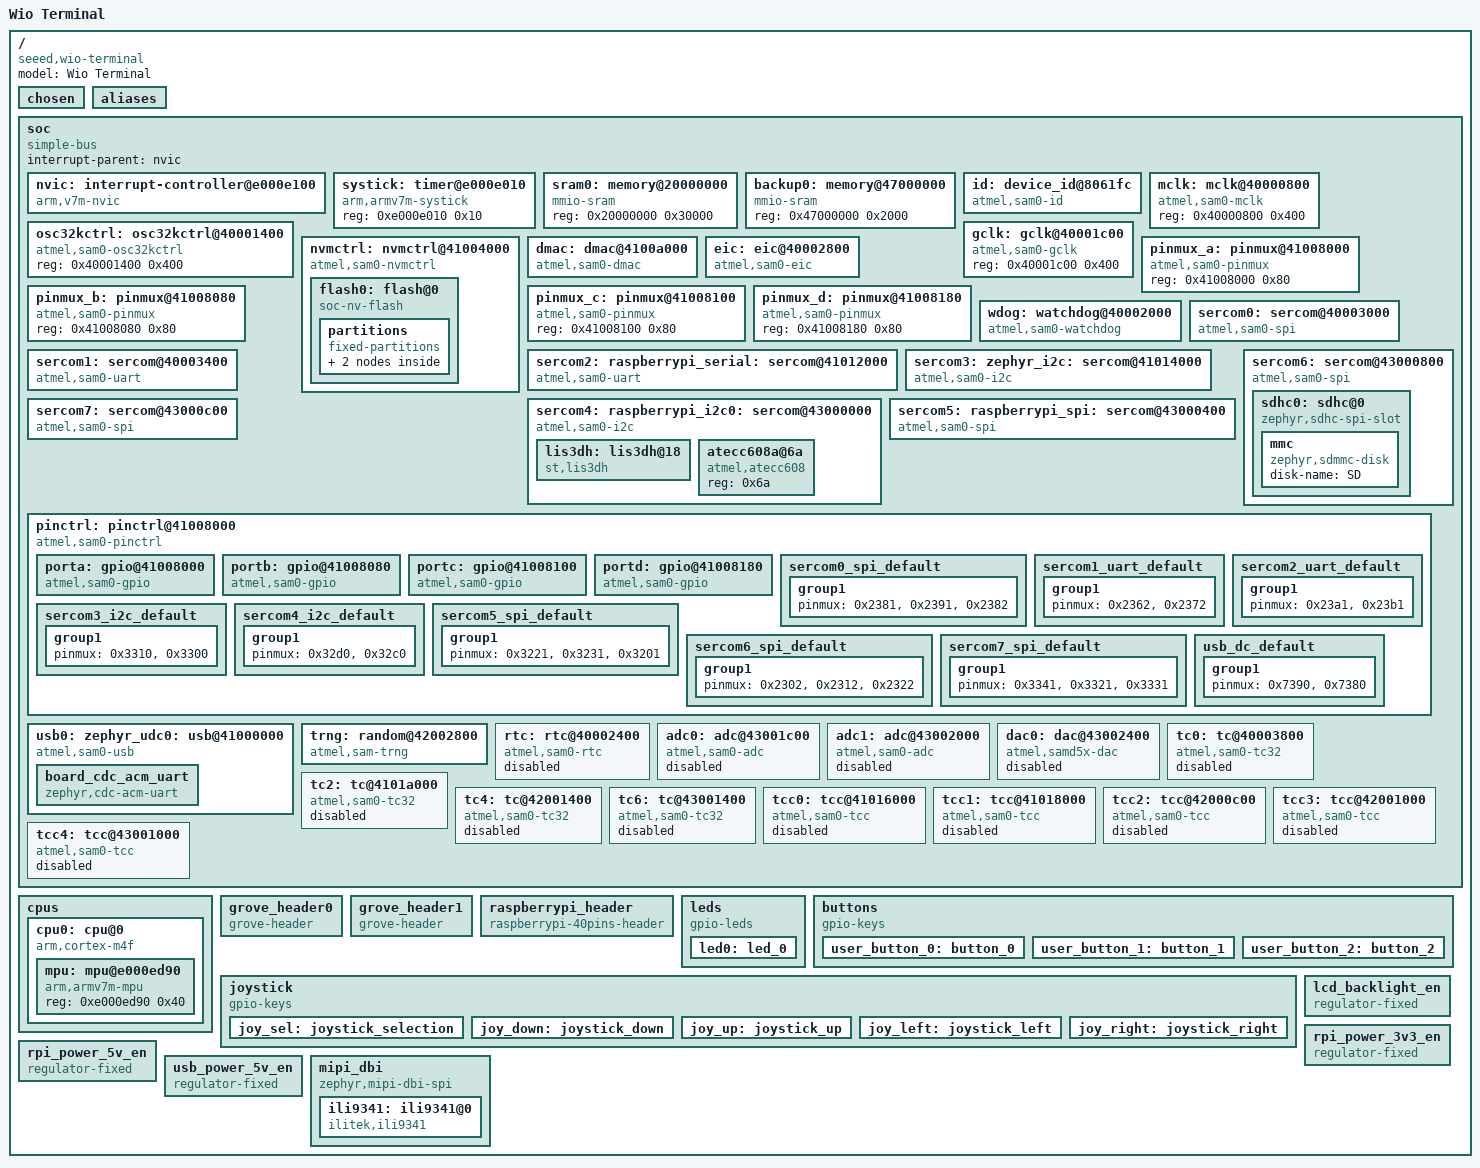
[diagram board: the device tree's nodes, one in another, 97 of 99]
/dts-v1/;

/* node '/' defined in zephyr/dts/common/skeleton.dtsi:9 */
/ {
	#address-cells = < 0x1 >;          /* in zephyr/dts/common/skeleton.dtsi:10 */
	#size-cells = < 0x1 >;             /* in zephyr/dts/common/skeleton.dtsi:11 */
	model = "Wio Terminal";            /* in zephyr/boards/seeed/wio_terminal/wio_terminal.dts:15 */
	compatible = "seeed,wio-terminal"; /* in zephyr/boards/seeed/wio_terminal/wio_terminal.dts:16 */

	/* node '/chosen' defined in zephyr/dts/common/skeleton.dtsi:13 */
	chosen {
		zephyr,entropy = &trng;                   /* in zephyr/dts/arm/atmel/samd5x.dtsi:51 */
		zephyr,flash-controller = &nvmctrl;       /* in zephyr/dts/arm/atmel/samd5x.dtsi:52 */
		zephyr,sram = &sram0;                     /* in zephyr/boards/seeed/wio_terminal/wio_terminal.dts:19 */
		zephyr,flash = &flash0;                   /* in zephyr/boards/seeed/wio_terminal/wio_terminal.dts:20 */
		zephyr,code-partition = &code_partition;  /* in zephyr/boards/seeed/wio_terminal/wio_terminal.dts:21 */
		zephyr,display = &ili9341;                /* in zephyr/boards/seeed/wio_terminal/wio_terminal.dts:22 */
		zephyr,console = &board_cdc_acm_uart;     /* in zephyr/boards/common/usb/cdc_acm_serial.dtsi:9 */
		zephyr,shell-uart = &board_cdc_acm_uart;  /* in zephyr/boards/common/usb/cdc_acm_serial.dtsi:10 */
		zephyr,uart-mcumgr = &board_cdc_acm_uart; /* in zephyr/boards/common/usb/cdc_acm_serial.dtsi:11 */
		zephyr,bt-mon-uart = &board_cdc_acm_uart; /* in zephyr/boards/common/usb/cdc_acm_serial.dtsi:12 */
		zephyr,bt-c2h-uart = &board_cdc_acm_uart; /* in zephyr/boards/common/usb/cdc_acm_serial.dtsi:13 */
	};

	/* node '/aliases' defined in zephyr/dts/common/skeleton.dtsi:15 */
	aliases {
		adc-0 = &adc0;        /* in zephyr/dts/arm/atmel/samd5x.dtsi:16 */
		adc-1 = &adc1;        /* in zephyr/dts/arm/atmel/samd5x.dtsi:17 */
		port-a = &porta;      /* in zephyr/dts/arm/atmel/samd5x.dtsi:19 */
		port-b = &portb;      /* in zephyr/dts/arm/atmel/samd5x.dtsi:20 */
		port-c = &portc;      /* in zephyr/dts/arm/atmel/samd5x.dtsi:21 */
		port-d = &portd;      /* in zephyr/dts/arm/atmel/samd5x.dtsi:22 */
		rtc = &rtc;           /* in zephyr/dts/arm/atmel/samd5x.dtsi:24 */
		sercom-0 = &sercom0;  /* in zephyr/dts/arm/atmel/samd5x.dtsi:26 */
		sercom-1 = &sercom1;  /* in zephyr/dts/arm/atmel/samd5x.dtsi:27 */
		sercom-2 = &sercom2;  /* in zephyr/dts/arm/atmel/samd5x.dtsi:28 */
		sercom-3 = &sercom3;  /* in zephyr/dts/arm/atmel/samd5x.dtsi:29 */
		sercom-4 = &sercom4;  /* in zephyr/dts/arm/atmel/samd5x.dtsi:30 */
		sercom-5 = &sercom5;  /* in zephyr/dts/arm/atmel/samd5x.dtsi:31 */
		sercom-6 = &sercom6;  /* in zephyr/dts/arm/atmel/samd5x.dtsi:32 */
		sercom-7 = &sercom7;  /* in zephyr/dts/arm/atmel/samd5x.dtsi:33 */
		tc-0 = &tc0;          /* in zephyr/dts/arm/atmel/samd5x.dtsi:35 */
		tc-2 = &tc2;          /* in zephyr/dts/arm/atmel/samd5x.dtsi:36 */
		tc-4 = &tc4;          /* in zephyr/dts/arm/atmel/samd5x.dtsi:37 */
		tc-6 = &tc6;          /* in zephyr/dts/arm/atmel/samd5x.dtsi:38 */
		tcc-0 = &tcc0;        /* in zephyr/dts/arm/atmel/samd5x.dtsi:40 */
		tcc-1 = &tcc1;        /* in zephyr/dts/arm/atmel/samd5x.dtsi:41 */
		tcc-2 = &tcc2;        /* in zephyr/dts/arm/atmel/samd5x.dtsi:42 */
		tcc-3 = &tcc3;        /* in zephyr/dts/arm/atmel/samd5x.dtsi:43 */
		tcc-4 = &tcc4;        /* in zephyr/dts/arm/atmel/samd5x.dtsi:44 */
		watchdog0 = &wdog;    /* in zephyr/dts/arm/atmel/samd5x.dtsi:46 */
		led0 = &led0;         /* in zephyr/boards/seeed/wio_terminal/wio_terminal.dts:27 */
		sw0 = &user_button_0; /* in zephyr/boards/seeed/wio_terminal/wio_terminal.dts:28 */
		sw1 = &user_button_1; /* in zephyr/boards/seeed/wio_terminal/wio_terminal.dts:29 */
		sw2 = &user_button_2; /* in zephyr/boards/seeed/wio_terminal/wio_terminal.dts:30 */
		i2c0 = &sercom4;      /* in zephyr/boards/seeed/wio_terminal/wio_terminal.dts:31 */
		i2c1 = &sercom3;      /* in zephyr/boards/seeed/wio_terminal/wio_terminal.dts:32 */
		spi0 = &sercom5;      /* in zephyr/boards/seeed/wio_terminal/wio_terminal.dts:33 */
		uart0 = &sercom2;     /* in zephyr/boards/seeed/wio_terminal/wio_terminal.dts:34 */
		accel0 = &lis3dh;     /* in zephyr/boards/seeed/wio_terminal/wio_terminal.dts:35 */
		sdhc0 = &sdhc0;       /* in zephyr/boards/seeed/wio_terminal/wio_terminal.dts:36 */
	};

	/* node '/soc' defined in zephyr/dts/arm/armv7-m.dtsi:6 */
	soc {
		#address-cells = < 0x1 >;     /* in zephyr/dts/arm/armv7-m.dtsi:7 */
		#size-cells = < 0x1 >;        /* in zephyr/dts/arm/armv7-m.dtsi:8 */
		compatible = "simple-bus";    /* in zephyr/dts/arm/armv7-m.dtsi:9 */
		interrupt-parent = < &nvic >; /* in zephyr/dts/arm/armv7-m.dtsi:10 */
		ranges;                       /* in zephyr/dts/arm/armv7-m.dtsi:11 */

		/* node '/soc/interrupt-controller@e000e100' defined in zephyr/dts/arm/armv7-m.dtsi:13 */
		nvic: interrupt-controller@e000e100 {
			#address-cells = < 0x1 >;            /* in zephyr/dts/arm/armv7-m.dtsi:14 */
			compatible = "arm,v7m-nvic";         /* in zephyr/dts/arm/armv7-m.dtsi:15 */
			reg = < 0xe000e100 0xc00 >;          /* in zephyr/dts/arm/armv7-m.dtsi:16 */
			interrupt-controller;                /* in zephyr/dts/arm/armv7-m.dtsi:17 */
			#interrupt-cells = < 0x2 >;          /* in zephyr/dts/arm/armv7-m.dtsi:18 */
			arm,num-irq-priority-bits = < 0x3 >; /* in zephyr/dts/arm/atmel/samd5x.dtsi:522 */
			phandle = < 0x1 >;                   /* in zephyr/dts/arm/armv7-m.dtsi:10 */
		};

		/* node '/soc/timer@e000e010' defined in zephyr/dts/arm/armv7-m.dtsi:21 */
		systick: timer@e000e010 {
			compatible = "arm,armv7m-systick"; /* in zephyr/dts/arm/armv7-m.dtsi:22 */
			reg = < 0xe000e010 0x10 >;         /* in zephyr/dts/arm/armv7-m.dtsi:23 */
		};

		/* node '/soc/memory@20000000' defined in zephyr/dts/arm/atmel/samd5x.dtsi:76 */
		sram0: memory@20000000 {
			compatible = "mmio-sram";     /* in zephyr/dts/arm/atmel/samd5x.dtsi:77 */
			reg = < 0x20000000 0x30000 >; /* in zephyr/dts/arm/atmel/samd5xx19.dtsi:19 */
		};

		/* node '/soc/memory@47000000' defined in zephyr/dts/arm/atmel/samd5x.dtsi:81 */
		backup0: memory@47000000 {
			compatible = "mmio-sram";    /* in zephyr/dts/arm/atmel/samd5x.dtsi:82 */
			reg = < 0x47000000 0x2000 >; /* in zephyr/dts/arm/atmel/samd5x.dtsi:83 */
		};

		/* node '/soc/device_id@8061fc' defined in zephyr/dts/arm/atmel/samd5x.dtsi:86 */
		id: device_id@8061fc {
			compatible = "atmel,sam0-id"; /* in zephyr/dts/arm/atmel/samd5x.dtsi:87 */
			reg = < 0x8061fc 0x4 >,
			      < 0x806010 0x4 >,
			      < 0x806014 0x4 >,
			      < 0x806018 0x4 >;       /* in zephyr/dts/arm/atmel/samd5x.dtsi:88 */
		};

		/* node '/soc/mclk@40000800' defined in zephyr/dts/arm/atmel/samd5x.dtsi:94 */
		mclk: mclk@40000800 {
			compatible = "atmel,sam0-mclk"; /* in zephyr/dts/arm/atmel/samd5x.dtsi:95 */
			reg = < 0x40000800 0x400 >;     /* in zephyr/dts/arm/atmel/samd5x.dtsi:96 */
			#clock-cells = < 0x2 >;         /* in zephyr/dts/arm/atmel/samd5x.dtsi:98 */
			phandle = < 0x3 >;              /* in zephyr/dts/arm/atmel/samd5x.dtsi:181 */
		};

		/* node '/soc/osc32kctrl@40001400' defined in zephyr/dts/arm/atmel/samd5x.dtsi:101 */
		osc32kctrl: osc32kctrl@40001400 {
			compatible = "atmel,sam0-osc32kctrl";  /* in zephyr/dts/arm/atmel/samd5x.dtsi:102 */
			reg = < 0x40001400 0x400 >;            /* in zephyr/dts/arm/atmel/samd5x.dtsi:103 */
			#clock-cells = < 0x0 >;                /* in zephyr/dts/arm/atmel/samd5x.dtsi:104 */
			#atmel,assigned-clock-cells = < 0x1 >; /* in zephyr/dts/arm/atmel/samd5x.dtsi:105 */
			phandle = < 0xf >;                     /* in zephyr/dts/arm/atmel/samd5x.dtsi:332 */
		};

		/* node '/soc/gclk@40001c00' defined in zephyr/dts/arm/atmel/samd5x.dtsi:108 */
		gclk: gclk@40001c00 {
			compatible = "atmel,sam0-gclk";        /* in zephyr/dts/arm/atmel/samd5x.dtsi:109 */
			reg = < 0x40001c00 0x400 >;            /* in zephyr/dts/arm/atmel/samd5x.dtsi:110 */
			#clock-cells = < 0x1 >;                /* in zephyr/dts/arm/atmel/samd5x.dtsi:112 */
			#atmel,assigned-clock-cells = < 0x1 >; /* in zephyr/dts/arm/atmel/samd5x.dtsi:113 */
			phandle = < 0x2 >;                     /* in zephyr/dts/arm/atmel/samd5x.dtsi:181 */
		};

		/* node '/soc/nvmctrl@41004000' defined in zephyr/dts/arm/atmel/samd5x.dtsi:116 */
		nvmctrl: nvmctrl@41004000 {
			compatible = "atmel,sam0-nvmctrl"; /* in zephyr/dts/arm/atmel/samd5x.dtsi:117 */
			reg = < 0x41004000 0x22 >;         /* in zephyr/dts/arm/atmel/samd5x.dtsi:118 */
			interrupts = < 0x1d 0x0 >,
			             < 0x1e 0x0 >;         /* in zephyr/dts/arm/atmel/samd5x.dtsi:119 */
			#address-cells = < 0x1 >;          /* in zephyr/dts/arm/atmel/samd5x.dtsi:121 */
			#size-cells = < 0x1 >;             /* in zephyr/dts/arm/atmel/samd5x.dtsi:122 */
			lock-regions = < 0x20 >;           /* in zephyr/dts/arm/atmel/samd5x.dtsi:124 */

			/* node '/soc/nvmctrl@41004000/flash@0' defined in zephyr/dts/arm/atmel/samd5x.dtsi:126 */
			flash0: flash@0 {
				compatible = "soc-nv-flash"; /* in zephyr/dts/arm/atmel/samd5x.dtsi:127 */
				write-block-size = < 0x8 >;  /* in zephyr/dts/arm/atmel/samd5x.dtsi:129 */
				reg = < 0x0 0x80000 >;       /* in zephyr/dts/arm/atmel/samd5xx19.dtsi:14 */

				/* node '/soc/nvmctrl@41004000/flash@0/partitions' defined in zephyr/boards/seeed/wio_terminal/wio_terminal.dts:168 */
				partitions {
					compatible = "fixed-partitions"; /* in zephyr/boards/seeed/wio_terminal/wio_terminal.dts:169 */
					#address-cells = < 0x1 >;        /* in zephyr/boards/seeed/wio_terminal/wio_terminal.dts:170 */
					#size-cells = < 0x1 >;           /* in zephyr/boards/seeed/wio_terminal/wio_terminal.dts:171 */

					/* node '/soc/nvmctrl@41004000/flash@0/partitions/partition@0' defined in zephyr/boards/seeed/wio_terminal/wio_terminal.dts:173 */
					boot_partition: partition@0 {
						label = "uf2";        /* in zephyr/boards/seeed/wio_terminal/wio_terminal.dts:174 */
						reg = < 0x0 0x4000 >; /* in zephyr/boards/seeed/wio_terminal/wio_terminal.dts:175 */
						read-only;            /* in zephyr/boards/seeed/wio_terminal/wio_terminal.dts:176 */
					};

					/* node '/soc/nvmctrl@41004000/flash@0/partitions/partition@4000' defined in zephyr/boards/seeed/wio_terminal/wio_terminal.dts:179 */
					code_partition: partition@4000 {
						label = "code";           /* in zephyr/boards/seeed/wio_terminal/wio_terminal.dts:180 */
						reg = < 0x4000 0x7c000 >; /* in zephyr/boards/seeed/wio_terminal/wio_terminal.dts:181 */
						read-only;                /* in zephyr/boards/seeed/wio_terminal/wio_terminal.dts:182 */
					};
				};
			};
		};

		/* node '/soc/dmac@4100a000' defined in zephyr/dts/arm/atmel/samd5x.dtsi:133 */
		dmac: dmac@4100a000 {
			compatible = "atmel,sam0-dmac"; /* in zephyr/dts/arm/atmel/samd5x.dtsi:134 */
			reg = < 0x4100a000 0x50 >;      /* in zephyr/dts/arm/atmel/samd5x.dtsi:135 */
			interrupts = < 0x1f 0x0 >,
			             < 0x20 0x0 >,
			             < 0x21 0x0 >,
			             < 0x22 0x0 >,
			             < 0x23 0x0 >;      /* in zephyr/dts/arm/atmel/samd5x.dtsi:136 */
			#dma-cells = < 0x2 >;           /* in zephyr/dts/arm/atmel/samd5x.dtsi:139 */
			status = "okay";                /* in zephyr/boards/seeed/wio_terminal/wio_terminal.dts:164 */
		};

		/* node '/soc/eic@40002800' defined in zephyr/dts/arm/atmel/samd5x.dtsi:142 */
		eic: eic@40002800 {
			compatible = "atmel,sam0-eic"; /* in zephyr/dts/arm/atmel/samd5x.dtsi:143 */
			reg = < 0x40002800 0x38 >;     /* in zephyr/dts/arm/atmel/samd5x.dtsi:144 */
			interrupts = < 0xc 0x0 >,
			             < 0xd 0x0 >,
			             < 0xe 0x0 >,
			             < 0xf 0x0 >,
			             < 0x10 0x0 >,
			             < 0x11 0x0 >,
			             < 0x12 0x0 >,
			             < 0x13 0x0 >,
			             < 0x14 0x0 >,
			             < 0x15 0x0 >,
			             < 0x16 0x0 >,
			             < 0x17 0x0 >,
			             < 0x18 0x0 >,
			             < 0x19 0x0 >,
			             < 0x1a 0x0 >,
			             < 0x1b 0x0 >;     /* in zephyr/dts/arm/atmel/samd5x.dtsi:145 */
		};

		/* node '/soc/pinmux@41008000' defined in zephyr/dts/arm/atmel/samd5x.dtsi:151 */
		pinmux_a: pinmux@41008000 {
			compatible = "atmel,sam0-pinmux"; /* in zephyr/dts/arm/atmel/samd5x.dtsi:152 */
			reg = < 0x41008000 0x80 >;        /* in zephyr/dts/arm/atmel/samd5x.dtsi:153 */
		};

		/* node '/soc/pinmux@41008080' defined in zephyr/dts/arm/atmel/samd5x.dtsi:156 */
		pinmux_b: pinmux@41008080 {
			compatible = "atmel,sam0-pinmux"; /* in zephyr/dts/arm/atmel/samd5x.dtsi:157 */
			reg = < 0x41008080 0x80 >;        /* in zephyr/dts/arm/atmel/samd5x.dtsi:158 */
		};

		/* node '/soc/pinmux@41008100' defined in zephyr/dts/arm/atmel/samd5x.dtsi:161 */
		pinmux_c: pinmux@41008100 {
			compatible = "atmel,sam0-pinmux"; /* in zephyr/dts/arm/atmel/samd5x.dtsi:162 */
			reg = < 0x41008100 0x80 >;        /* in zephyr/dts/arm/atmel/samd5x.dtsi:163 */
		};

		/* node '/soc/pinmux@41008180' defined in zephyr/dts/arm/atmel/samd5x.dtsi:166 */
		pinmux_d: pinmux@41008180 {
			compatible = "atmel,sam0-pinmux"; /* in zephyr/dts/arm/atmel/samd5x.dtsi:167 */
			reg = < 0x41008180 0x80 >;        /* in zephyr/dts/arm/atmel/samd5x.dtsi:168 */
		};

		/* node '/soc/watchdog@40002000' defined in zephyr/dts/arm/atmel/samd5x.dtsi:171 */
		wdog: watchdog@40002000 {
			compatible = "atmel,sam0-watchdog"; /* in zephyr/dts/arm/atmel/samd5x.dtsi:172 */
			reg = < 0x40002000 0xd >;           /* in zephyr/dts/arm/atmel/samd5x.dtsi:173 */
			interrupts = < 0xa 0x0 >;           /* in zephyr/dts/arm/atmel/samd5x.dtsi:174 */
		};

		/* node '/soc/sercom@40003000' defined in zephyr/dts/arm/atmel/samd5x.dtsi:177 */
		sercom0: sercom@40003000 {
			reg = < 0x40003000 0x40 >;             /* in zephyr/dts/arm/atmel/samd5x.dtsi:179 */
			interrupts = < 0x2e 0x0 >,
			             < 0x2f 0x0 >,
			             < 0x30 0x0 >,
			             < 0x31 0x0 >;             /* in zephyr/dts/arm/atmel/samd5x.dtsi:180 */
			clocks = < &gclk 0x7 >,
			         < &mclk 0x14 0xc >;           /* in zephyr/dts/arm/atmel/samd5x.dtsi:181 */
			clock-names = "GCLK",
			              "MCLK";                  /* in zephyr/dts/arm/atmel/samd5x.dtsi:182 */
			atmel,assigned-clocks = < &gclk 0x0 >; /* in zephyr/dts/arm/atmel/samd5x.dtsi:183 */
			atmel,assigned-clock-names = "GCLK";   /* in zephyr/dts/arm/atmel/samd5x.dtsi:184 */
			status = "okay";                       /* in zephyr/boards/seeed/wio_terminal/wio_terminal.dts:189 */
			compatible = "atmel,sam0-spi";         /* in zephyr/boards/seeed/wio_terminal/wio_terminal.dts:190 */
			#address-cells = < 0x1 >;              /* in zephyr/boards/seeed/wio_terminal/wio_terminal.dts:191 */
			#size-cells = < 0x0 >;                 /* in zephyr/boards/seeed/wio_terminal/wio_terminal.dts:192 */
			dipo = < 0x2 >;                        /* in zephyr/boards/seeed/wio_terminal/wio_terminal.dts:193 */
			dopo = < 0x0 >;                        /* in zephyr/boards/seeed/wio_terminal/wio_terminal.dts:194 */
			pinctrl-0 = < &sercom0_spi_default >;  /* in zephyr/boards/seeed/wio_terminal/wio_terminal.dts:195 */
			pinctrl-names = "default";             /* in zephyr/boards/seeed/wio_terminal/wio_terminal.dts:196 */
			cs-gpios = < &portc 0x19 0x1 >;        /* in zephyr/boards/seeed/wio_terminal/wio_terminal.dts:197 */
		};

		/* node '/soc/sercom@40003400' defined in zephyr/dts/arm/atmel/samd5x.dtsi:188 */
		sercom1: sercom@40003400 {
			reg = < 0x40003400 0x40 >;             /* in zephyr/dts/arm/atmel/samd5x.dtsi:190 */
			interrupts = < 0x32 0x0 >,
			             < 0x33 0x0 >,
			             < 0x34 0x0 >,
			             < 0x35 0x0 >;             /* in zephyr/dts/arm/atmel/samd5x.dtsi:191 */
			clocks = < &gclk 0x8 >,
			         < &mclk 0x14 0xd >;           /* in zephyr/dts/arm/atmel/samd5x.dtsi:192 */
			clock-names = "GCLK",
			              "MCLK";                  /* in zephyr/dts/arm/atmel/samd5x.dtsi:193 */
			atmel,assigned-clocks = < &gclk 0x0 >; /* in zephyr/dts/arm/atmel/samd5x.dtsi:194 */
			atmel,assigned-clock-names = "GCLK";   /* in zephyr/dts/arm/atmel/samd5x.dtsi:195 */
			status = "okay";                       /* in zephyr/boards/seeed/wio_terminal/wio_terminal.dts:202 */
			compatible = "atmel,sam0-uart";        /* in zephyr/boards/seeed/wio_terminal/wio_terminal.dts:203 */
			current-speed = < 0x1c200 >;           /* in zephyr/boards/seeed/wio_terminal/wio_terminal.dts:204 */
			rxpo = < 0x1 >;                        /* in zephyr/boards/seeed/wio_terminal/wio_terminal.dts:205 */
			txpo = < 0x0 >;                        /* in zephyr/boards/seeed/wio_terminal/wio_terminal.dts:206 */
			pinctrl-0 = < &sercom1_uart_default >; /* in zephyr/boards/seeed/wio_terminal/wio_terminal.dts:207 */
			pinctrl-names = "default";             /* in zephyr/boards/seeed/wio_terminal/wio_terminal.dts:208 */
		};

		/* node '/soc/sercom@41012000' defined in zephyr/dts/arm/atmel/samd5x.dtsi:199 */
		sercom2: raspberrypi_serial: sercom@41012000 {
			reg = < 0x41012000 0x40 >;             /* in zephyr/dts/arm/atmel/samd5x.dtsi:201 */
			interrupts = < 0x36 0x0 >,
			             < 0x37 0x0 >,
			             < 0x38 0x0 >,
			             < 0x39 0x0 >;             /* in zephyr/dts/arm/atmel/samd5x.dtsi:202 */
			clocks = < &gclk 0x17 >,
			         < &mclk 0x18 0x9 >;           /* in zephyr/dts/arm/atmel/samd5x.dtsi:203 */
			clock-names = "GCLK",
			              "MCLK";                  /* in zephyr/dts/arm/atmel/samd5x.dtsi:204 */
			atmel,assigned-clocks = < &gclk 0x0 >; /* in zephyr/dts/arm/atmel/samd5x.dtsi:205 */
			atmel,assigned-clock-names = "GCLK";   /* in zephyr/dts/arm/atmel/samd5x.dtsi:206 */
			status = "okay";                       /* in zephyr/boards/seeed/wio_terminal/wio_terminal.dts:213 */
			compatible = "atmel,sam0-uart";        /* in zephyr/boards/seeed/wio_terminal/wio_terminal.dts:214 */
			current-speed = < 0x1c200 >;           /* in zephyr/boards/seeed/wio_terminal/wio_terminal.dts:215 */
			rxpo = < 0x1 >;                        /* in zephyr/boards/seeed/wio_terminal/wio_terminal.dts:216 */
			txpo = < 0x0 >;                        /* in zephyr/boards/seeed/wio_terminal/wio_terminal.dts:217 */
			pinctrl-0 = < &sercom2_uart_default >; /* in zephyr/boards/seeed/wio_terminal/wio_terminal.dts:218 */
			pinctrl-names = "default";             /* in zephyr/boards/seeed/wio_terminal/wio_terminal.dts:219 */
		};

		/* node '/soc/sercom@41014000' defined in zephyr/dts/arm/atmel/samd5x.dtsi:210 */
		sercom3: zephyr_i2c: raspberrypi_i2c1: sercom@41014000 {
			reg = < 0x41014000 0x40 >;             /* in zephyr/dts/arm/atmel/samd5x.dtsi:212 */
			interrupts = < 0x3a 0x0 >,
			             < 0x3b 0x0 >,
			             < 0x3c 0x0 >,
			             < 0x3d 0x0 >;             /* in zephyr/dts/arm/atmel/samd5x.dtsi:213 */
			clocks = < &gclk 0x18 >,
			         < &mclk 0x18 0xa >;           /* in zephyr/dts/arm/atmel/samd5x.dtsi:214 */
			clock-names = "GCLK",
			              "MCLK";                  /* in zephyr/dts/arm/atmel/samd5x.dtsi:215 */
			atmel,assigned-clocks = < &gclk 0x0 >; /* in zephyr/dts/arm/atmel/samd5x.dtsi:216 */
			atmel,assigned-clock-names = "GCLK";   /* in zephyr/dts/arm/atmel/samd5x.dtsi:217 */
			status = "okay";                       /* in zephyr/boards/seeed/wio_terminal/wio_terminal.dts:224 */
			compatible = "atmel,sam0-i2c";         /* in zephyr/boards/seeed/wio_terminal/wio_terminal.dts:225 */
			clock-frequency = < 0x61a80 >;         /* in zephyr/boards/seeed/wio_terminal/wio_terminal.dts:226 */
			#address-cells = < 0x1 >;              /* in zephyr/boards/seeed/wio_terminal/wio_terminal.dts:227 */
			#size-cells = < 0x0 >;                 /* in zephyr/boards/seeed/wio_terminal/wio_terminal.dts:228 */
			pinctrl-0 = < &sercom3_i2c_default >;  /* in zephyr/boards/seeed/wio_terminal/wio_terminal.dts:229 */
			pinctrl-names = "default";             /* in zephyr/boards/seeed/wio_terminal/wio_terminal.dts:230 */
		};

		/* node '/soc/sercom@43000000' defined in zephyr/dts/arm/atmel/samd5x.dtsi:221 */
		sercom4: raspberrypi_i2c0: sercom@43000000 {
			reg = < 0x43000000 0x40 >;             /* in zephyr/dts/arm/atmel/samd5x.dtsi:223 */
			interrupts = < 0x3e 0x0 >,
			             < 0x3f 0x0 >,
			             < 0x40 0x0 >,
			             < 0x41 0x0 >;             /* in zephyr/dts/arm/atmel/samd5x.dtsi:224 */
			clocks = < &gclk 0x22 >,
			         < &mclk 0x20 0x0 >;           /* in zephyr/dts/arm/atmel/samd5x.dtsi:225 */
			clock-names = "GCLK",
			              "MCLK";                  /* in zephyr/dts/arm/atmel/samd5x.dtsi:226 */
			atmel,assigned-clocks = < &gclk 0x0 >; /* in zephyr/dts/arm/atmel/samd5x.dtsi:227 */
			atmel,assigned-clock-names = "GCLK";   /* in zephyr/dts/arm/atmel/samd5x.dtsi:228 */
			status = "okay";                       /* in zephyr/boards/seeed/wio_terminal/wio_terminal.dts:235 */
			compatible = "atmel,sam0-i2c";         /* in zephyr/boards/seeed/wio_terminal/wio_terminal.dts:236 */
			clock-frequency = < 0x33e140 >;        /* in zephyr/boards/seeed/wio_terminal/wio_terminal.dts:237 */
			#address-cells = < 0x1 >;              /* in zephyr/boards/seeed/wio_terminal/wio_terminal.dts:238 */
			#size-cells = < 0x0 >;                 /* in zephyr/boards/seeed/wio_terminal/wio_terminal.dts:239 */
			pinctrl-0 = < &sercom4_i2c_default >;  /* in zephyr/boards/seeed/wio_terminal/wio_terminal.dts:240 */
			pinctrl-names = "default";             /* in zephyr/boards/seeed/wio_terminal/wio_terminal.dts:241 */

			/* node '/soc/sercom@43000000/lis3dh@18' defined in zephyr/boards/seeed/wio_terminal/wio_terminal.dts:244 */
			lis3dh: lis3dh@18 {
				compatible = "st,lis3dh",
				             "st,lis2dh";        /* in zephyr/boards/seeed/wio_terminal/wio_terminal.dts:245 */
				status = "okay";                 /* in zephyr/boards/seeed/wio_terminal/wio_terminal.dts:246 */
				reg = < 0x18 >;                  /* in zephyr/boards/seeed/wio_terminal/wio_terminal.dts:247 */
				irq-gpios = < &portc 0x15 0x0 >; /* in zephyr/boards/seeed/wio_terminal/wio_terminal.dts:248 */
			};

			/* node '/soc/sercom@43000000/atecc608a@6a' defined in zephyr/boards/seeed/wio_terminal/wio_terminal.dts:252 */
			atecc608a@6a {
				compatible = "atmel,atecc608"; /* in zephyr/boards/seeed/wio_terminal/wio_terminal.dts:253 */
				reg = < 0x6a >;                /* in zephyr/boards/seeed/wio_terminal/wio_terminal.dts:254 */
			};
		};

		/* node '/soc/sercom@43000400' defined in zephyr/dts/arm/atmel/samd5x.dtsi:232 */
		sercom5: raspberrypi_spi: sercom@43000400 {
			reg = < 0x43000400 0x40 >;             /* in zephyr/dts/arm/atmel/samd5x.dtsi:234 */
			interrupts = < 0x42 0x0 >,
			             < 0x43 0x0 >,
			             < 0x44 0x0 >,
			             < 0x45 0x0 >;             /* in zephyr/dts/arm/atmel/samd5x.dtsi:235 */
			clocks = < &gclk 0x23 >,
			         < &mclk 0x20 0x1 >;           /* in zephyr/dts/arm/atmel/samd5x.dtsi:236 */
			clock-names = "GCLK",
			              "MCLK";                  /* in zephyr/dts/arm/atmel/samd5x.dtsi:237 */
			atmel,assigned-clocks = < &gclk 0x0 >; /* in zephyr/dts/arm/atmel/samd5x.dtsi:238 */
			atmel,assigned-clock-names = "GCLK";   /* in zephyr/dts/arm/atmel/samd5x.dtsi:239 */
			status = "okay";                       /* in zephyr/boards/seeed/wio_terminal/wio_terminal.dts:260 */
			compatible = "atmel,sam0-spi";         /* in zephyr/boards/seeed/wio_terminal/wio_terminal.dts:261 */
			#address-cells = < 0x1 >;              /* in zephyr/boards/seeed/wio_terminal/wio_terminal.dts:262 */
			#size-cells = < 0x0 >;                 /* in zephyr/boards/seeed/wio_terminal/wio_terminal.dts:263 */
			dipo = < 0x2 >;                        /* in zephyr/boards/seeed/wio_terminal/wio_terminal.dts:264 */
			dopo = < 0x0 >;                        /* in zephyr/boards/seeed/wio_terminal/wio_terminal.dts:265 */
			pinctrl-0 = < &sercom5_spi_default >;  /* in zephyr/boards/seeed/wio_terminal/wio_terminal.dts:266 */
			pinctrl-names = "default";             /* in zephyr/boards/seeed/wio_terminal/wio_terminal.dts:267 */
			cs-gpios = < &portb 0x1 0x1 >;         /* in zephyr/boards/seeed/wio_terminal/wio_terminal.dts:268 */
		};

		/* node '/soc/sercom@43000800' defined in zephyr/dts/arm/atmel/samd5x.dtsi:243 */
		sercom6: sercom@43000800 {
			reg = < 0x43000800 0x40 >;             /* in zephyr/dts/arm/atmel/samd5x.dtsi:245 */
			interrupts = < 0x46 0x0 >,
			             < 0x47 0x0 >,
			             < 0x48 0x0 >,
			             < 0x49 0x0 >;             /* in zephyr/dts/arm/atmel/samd5x.dtsi:246 */
			clocks = < &gclk 0x24 >,
			         < &mclk 0x20 0x2 >;           /* in zephyr/dts/arm/atmel/samd5x.dtsi:247 */
			clock-names = "GCLK",
			              "MCLK";                  /* in zephyr/dts/arm/atmel/samd5x.dtsi:248 */
			atmel,assigned-clocks = < &gclk 0x0 >; /* in zephyr/dts/arm/atmel/samd5x.dtsi:249 */
			atmel,assigned-clock-names = "GCLK";   /* in zephyr/dts/arm/atmel/samd5x.dtsi:250 */
			status = "okay";                       /* in zephyr/boards/seeed/wio_terminal/wio_terminal.dts:273 */
			compatible = "atmel,sam0-spi";         /* in zephyr/boards/seeed/wio_terminal/wio_terminal.dts:274 */
			#address-cells = < 0x1 >;              /* in zephyr/boards/seeed/wio_terminal/wio_terminal.dts:275 */
			#size-cells = < 0x0 >;                 /* in zephyr/boards/seeed/wio_terminal/wio_terminal.dts:276 */
			dipo = < 0x2 >;                        /* in zephyr/boards/seeed/wio_terminal/wio_terminal.dts:277 */
			dopo = < 0x0 >;                        /* in zephyr/boards/seeed/wio_terminal/wio_terminal.dts:278 */
			pinctrl-0 = < &sercom6_spi_default >;  /* in zephyr/boards/seeed/wio_terminal/wio_terminal.dts:279 */
			pinctrl-names = "default";             /* in zephyr/boards/seeed/wio_terminal/wio_terminal.dts:280 */
			cs-gpios = < &portc 0x13 0x1 >;        /* in zephyr/boards/seeed/wio_terminal/wio_terminal.dts:281 */

			/* node '/soc/sercom@43000800/sdhc@0' defined in zephyr/boards/seeed/wio_terminal/wio_terminal.dts:284 */
			sdhc0: sdhc@0 {
				compatible = "zephyr,sdhc-spi-slot"; /* in zephyr/boards/seeed/wio_terminal/wio_terminal.dts:285 */
				reg = < 0x0 >;                       /* in zephyr/boards/seeed/wio_terminal/wio_terminal.dts:286 */
				spi-max-frequency = < 0x16e3600 >;   /* in zephyr/boards/seeed/wio_terminal/wio_terminal.dts:287 */

				/* node '/soc/sercom@43000800/sdhc@0/mmc' defined in zephyr/boards/seeed/wio_terminal/wio_terminal.dts:289 */
				mmc {
					compatible = "zephyr,sdmmc-disk"; /* in zephyr/boards/seeed/wio_terminal/wio_terminal.dts:290 */
					disk-name = "SD";                 /* in zephyr/boards/seeed/wio_terminal/wio_terminal.dts:291 */
				};
			};
		};

		/* node '/soc/sercom@43000c00' defined in zephyr/dts/arm/atmel/samd5x.dtsi:254 */
		sercom7: sercom@43000c00 {
			reg = < 0x43000c00 0x40 >;             /* in zephyr/dts/arm/atmel/samd5x.dtsi:256 */
			interrupts = < 0x4a 0x0 >,
			             < 0x4b 0x0 >,
			             < 0x4c 0x0 >,
			             < 0x4d 0x0 >;             /* in zephyr/dts/arm/atmel/samd5x.dtsi:257 */
			clocks = < &gclk 0x25 >,
			         < &mclk 0x20 0x3 >;           /* in zephyr/dts/arm/atmel/samd5x.dtsi:258 */
			clock-names = "GCLK",
			              "MCLK";                  /* in zephyr/dts/arm/atmel/samd5x.dtsi:259 */
			atmel,assigned-clocks = < &gclk 0x0 >; /* in zephyr/dts/arm/atmel/samd5x.dtsi:260 */
			atmel,assigned-clock-names = "GCLK";   /* in zephyr/dts/arm/atmel/samd5x.dtsi:261 */
			status = "okay";                       /* in zephyr/boards/seeed/wio_terminal/wio_terminal.dts:298 */
			compatible = "atmel,sam0-spi";         /* in zephyr/boards/seeed/wio_terminal/wio_terminal.dts:299 */
			#address-cells = < 0x1 >;              /* in zephyr/boards/seeed/wio_terminal/wio_terminal.dts:300 */
			#size-cells = < 0x0 >;                 /* in zephyr/boards/seeed/wio_terminal/wio_terminal.dts:301 */
			dipo = < 0x2 >;                        /* in zephyr/boards/seeed/wio_terminal/wio_terminal.dts:302 */
			dopo = < 0x3 >;                        /* in zephyr/boards/seeed/wio_terminal/wio_terminal.dts:303 */
			pinctrl-0 = < &sercom7_spi_default >;  /* in zephyr/boards/seeed/wio_terminal/wio_terminal.dts:304 */
			pinctrl-names = "default";             /* in zephyr/boards/seeed/wio_terminal/wio_terminal.dts:305 */
			cs-gpios = < &portb 0x15 0x1 >;        /* in zephyr/boards/seeed/wio_terminal/wio_terminal.dts:306 */
			phandle = < 0x12 >;                    /* in zephyr/boards/seeed/wio_terminal/wio_terminal.dts:144 */
		};

		/* node '/soc/pinctrl@41008000' defined in zephyr/dts/arm/atmel/samd5x.dtsi:265 */
		pinctrl: pinctrl@41008000 {
			compatible = "atmel,sam0-pinctrl";        /* in zephyr/dts/arm/atmel/samd5x.dtsi:266 */
			ranges = < 0x41008000 0x41008000 0x200 >; /* in zephyr/dts/arm/atmel/samd5x.dtsi:267 */
			#address-cells = < 0x1 >;                 /* in zephyr/dts/arm/atmel/samd5x.dtsi:269 */
			#size-cells = < 0x1 >;                    /* in zephyr/dts/arm/atmel/samd5x.dtsi:270 */

			/* node '/soc/pinctrl@41008000/gpio@41008000' defined in zephyr/dts/arm/atmel/samd5x.dtsi:272 */
			porta: gpio@41008000 {
				compatible = "atmel,sam0-gpio"; /* in zephyr/dts/arm/atmel/samd5x.dtsi:273 */
				reg = < 0x41008000 0x80 >;      /* in zephyr/dts/arm/atmel/samd5x.dtsi:274 */
				#atmel,pin-cells = < 0x2 >;     /* in zephyr/dts/arm/atmel/samd5x.dtsi:276 */
				#gpio-cells = < 0x2 >;          /* in zephyr/dts/arm/atmel/samd5x.dtsi:277 */
				gpio-controller;                /* in zephyr/dts/arm/atmel/samd5x.dtsi:279 */
				phandle = < 0x10 >;             /* in zephyr/boards/seeed/wio_terminal/grove_connectors.dtsi:21 */
			};

			/* node '/soc/pinctrl@41008000/gpio@41008080' defined in zephyr/dts/arm/atmel/samd5x.dtsi:282 */
			portb: gpio@41008080 {
				compatible = "atmel,sam0-gpio"; /* in zephyr/dts/arm/atmel/samd5x.dtsi:283 */
				reg = < 0x41008080 0x80 >;      /* in zephyr/dts/arm/atmel/samd5x.dtsi:284 */
				#atmel,pin-cells = < 0x2 >;     /* in zephyr/dts/arm/atmel/samd5x.dtsi:286 */
				#gpio-cells = < 0x2 >;          /* in zephyr/dts/arm/atmel/samd5x.dtsi:287 */
				gpio-controller;                /* in zephyr/dts/arm/atmel/samd5x.dtsi:289 */
				phandle = < 0xb >;              /* in zephyr/boards/seeed/wio_terminal/wio_terminal.dts:268 */
			};

			/* node '/soc/pinctrl@41008000/gpio@41008100' defined in zephyr/dts/arm/atmel/samd5x.dtsi:292 */
			portc: gpio@41008100 {
				compatible = "atmel,sam0-gpio"; /* in zephyr/dts/arm/atmel/samd5x.dtsi:293 */
				reg = < 0x41008100 0x80 >;      /* in zephyr/dts/arm/atmel/samd5x.dtsi:294 */
				#atmel,pin-cells = < 0x2 >;     /* in zephyr/dts/arm/atmel/samd5x.dtsi:296 */
				#gpio-cells = < 0x2 >;          /* in zephyr/dts/arm/atmel/samd5x.dtsi:297 */
				gpio-controller;                /* in zephyr/dts/arm/atmel/samd5x.dtsi:299 */
				phandle = < 0x5 >;              /* in zephyr/boards/seeed/wio_terminal/wio_terminal.dts:197 */
			};

			/* node '/soc/pinctrl@41008000/gpio@41008180' defined in zephyr/dts/arm/atmel/samd5x.dtsi:302 */
			portd: gpio@41008180 {
				compatible = "atmel,sam0-gpio"; /* in zephyr/dts/arm/atmel/samd5x.dtsi:303 */
				reg = < 0x41008180 0x80 >;      /* in zephyr/dts/arm/atmel/samd5x.dtsi:304 */
				#atmel,pin-cells = < 0x2 >;     /* in zephyr/dts/arm/atmel/samd5x.dtsi:306 */
				#gpio-cells = < 0x2 >;          /* in zephyr/dts/arm/atmel/samd5x.dtsi:307 */
				gpio-controller;                /* in zephyr/dts/arm/atmel/samd5x.dtsi:309 */
				phandle = < 0x11 >;             /* in zephyr/boards/seeed/wio_terminal/wio_terminal.dts:80 */
			};

			/* node '/soc/pinctrl@41008000/sercom0_spi_default' defined in zephyr/boards/seeed/wio_terminal/wio_terminal-pinctrl.dtsi:9 */
			sercom0_spi_default: sercom0_spi_default {
				phandle = < 0x4 >; /* in zephyr/boards/seeed/wio_terminal/wio_terminal.dts:195 */

				/* node '/soc/pinctrl@41008000/sercom0_spi_default/group1' defined in zephyr/boards/seeed/wio_terminal/wio_terminal-pinctrl.dtsi:10 */
				group1 {
					pinmux = < 0x2381 >,
					         < 0x2391 >,
					         < 0x2382 >; /* in zephyr/boards/seeed/wio_terminal/wio_terminal-pinctrl.dtsi:11 */
				};
			};

			/* node '/soc/pinctrl@41008000/sercom1_uart_default' defined in zephyr/boards/seeed/wio_terminal/wio_terminal-pinctrl.dtsi:17 */
			sercom1_uart_default: sercom1_uart_default {
				phandle = < 0x6 >; /* in zephyr/boards/seeed/wio_terminal/wio_terminal.dts:207 */

				/* node '/soc/pinctrl@41008000/sercom1_uart_default/group1' defined in zephyr/boards/seeed/wio_terminal/wio_terminal-pinctrl.dtsi:18 */
				group1 {
					pinmux = < 0x2362 >,
					         < 0x2372 >; /* in zephyr/boards/seeed/wio_terminal/wio_terminal-pinctrl.dtsi:19 */
				};
			};

			/* node '/soc/pinctrl@41008000/sercom2_uart_default' defined in zephyr/boards/seeed/wio_terminal/wio_terminal-pinctrl.dtsi:24 */
			sercom2_uart_default: sercom2_uart_default {
				phandle = < 0x7 >; /* in zephyr/boards/seeed/wio_terminal/wio_terminal.dts:218 */

				/* node '/soc/pinctrl@41008000/sercom2_uart_default/group1' defined in zephyr/boards/seeed/wio_terminal/wio_terminal-pinctrl.dtsi:25 */
				group1 {
					pinmux = < 0x23a1 >,
					         < 0x23b1 >; /* in zephyr/boards/seeed/wio_terminal/wio_terminal-pinctrl.dtsi:26 */
				};
			};

			/* node '/soc/pinctrl@41008000/sercom3_i2c_default' defined in zephyr/boards/seeed/wio_terminal/wio_terminal-pinctrl.dtsi:31 */
			sercom3_i2c_default: sercom3_i2c_default {
				phandle = < 0x8 >; /* in zephyr/boards/seeed/wio_terminal/wio_terminal.dts:229 */

				/* node '/soc/pinctrl@41008000/sercom3_i2c_default/group1' defined in zephyr/boards/seeed/wio_terminal/wio_terminal-pinctrl.dtsi:32 */
				group1 {
					pinmux = < 0x3310 >,
					         < 0x3300 >; /* in zephyr/boards/seeed/wio_terminal/wio_terminal-pinctrl.dtsi:33 */
				};
			};

			/* node '/soc/pinctrl@41008000/sercom4_i2c_default' defined in zephyr/boards/seeed/wio_terminal/wio_terminal-pinctrl.dtsi:38 */
			sercom4_i2c_default: sercom4_i2c_default {
				phandle = < 0x9 >; /* in zephyr/boards/seeed/wio_terminal/wio_terminal.dts:240 */

				/* node '/soc/pinctrl@41008000/sercom4_i2c_default/group1' defined in zephyr/boards/seeed/wio_terminal/wio_terminal-pinctrl.dtsi:39 */
				group1 {
					pinmux = < 0x32d0 >,
					         < 0x32c0 >; /* in zephyr/boards/seeed/wio_terminal/wio_terminal-pinctrl.dtsi:40 */
				};
			};

			/* node '/soc/pinctrl@41008000/sercom5_spi_default' defined in zephyr/boards/seeed/wio_terminal/wio_terminal-pinctrl.dtsi:45 */
			sercom5_spi_default: sercom5_spi_default {
				phandle = < 0xa >; /* in zephyr/boards/seeed/wio_terminal/wio_terminal.dts:266 */

				/* node '/soc/pinctrl@41008000/sercom5_spi_default/group1' defined in zephyr/boards/seeed/wio_terminal/wio_terminal-pinctrl.dtsi:46 */
				group1 {
					pinmux = < 0x3221 >,
					         < 0x3231 >,
					         < 0x3201 >; /* in zephyr/boards/seeed/wio_terminal/wio_terminal-pinctrl.dtsi:47 */
				};
			};

			/* node '/soc/pinctrl@41008000/sercom6_spi_default' defined in zephyr/boards/seeed/wio_terminal/wio_terminal-pinctrl.dtsi:53 */
			sercom6_spi_default: sercom6_spi_default {
				phandle = < 0xc >; /* in zephyr/boards/seeed/wio_terminal/wio_terminal.dts:279 */

				/* node '/soc/pinctrl@41008000/sercom6_spi_default/group1' defined in zephyr/boards/seeed/wio_terminal/wio_terminal-pinctrl.dtsi:54 */
				group1 {
					pinmux = < 0x2302 >,
					         < 0x2312 >,
					         < 0x2322 >; /* in zephyr/boards/seeed/wio_terminal/wio_terminal-pinctrl.dtsi:55 */
				};
			};

			/* node '/soc/pinctrl@41008000/sercom7_spi_default' defined in zephyr/boards/seeed/wio_terminal/wio_terminal-pinctrl.dtsi:61 */
			sercom7_spi_default: sercom7_spi_default {
				phandle = < 0xd >; /* in zephyr/boards/seeed/wio_terminal/wio_terminal.dts:304 */

				/* node '/soc/pinctrl@41008000/sercom7_spi_default/group1' defined in zephyr/boards/seeed/wio_terminal/wio_terminal-pinctrl.dtsi:62 */
				group1 {
					pinmux = < 0x3341 >,
					         < 0x3321 >,
					         < 0x3331 >; /* in zephyr/boards/seeed/wio_terminal/wio_terminal-pinctrl.dtsi:63 */
				};
			};

			/* node '/soc/pinctrl@41008000/usb_dc_default' defined in zephyr/boards/seeed/wio_terminal/wio_terminal-pinctrl.dtsi:69 */
			usb_dc_default: usb_dc_default {
				phandle = < 0xe >; /* in zephyr/boards/seeed/wio_terminal/wio_terminal.dts:312 */

				/* node '/soc/pinctrl@41008000/usb_dc_default/group1' defined in zephyr/boards/seeed/wio_terminal/wio_terminal-pinctrl.dtsi:70 */
				group1 {
					pinmux = < 0x7390 >,
					         < 0x7380 >; /* in zephyr/boards/seeed/wio_terminal/wio_terminal-pinctrl.dtsi:71 */
				};
			};
		};

		/* node '/soc/usb@41000000' defined in zephyr/dts/arm/atmel/samd5x.dtsi:313 */
		usb0: zephyr_udc0: usb@41000000 {
			compatible = "atmel,sam0-usb";   /* in zephyr/dts/arm/atmel/samd5x.dtsi:314 */
			reg = < 0x41000000 0x1000 >;     /* in zephyr/dts/arm/atmel/samd5x.dtsi:315 */
			interrupts = < 0x50 0x0 >,
			             < 0x51 0x0 >,
			             < 0x52 0x0 >,
			             < 0x53 0x0 >;       /* in zephyr/dts/arm/atmel/samd5x.dtsi:316 */
			num-bidir-endpoints = < 0x8 >;   /* in zephyr/dts/arm/atmel/samd5x.dtsi:319 */
			status = "okay";                 /* in zephyr/boards/seeed/wio_terminal/wio_terminal.dts:311 */
			pinctrl-0 = < &usb_dc_default >; /* in zephyr/boards/seeed/wio_terminal/wio_terminal.dts:312 */
			pinctrl-names = "default";       /* in zephyr/boards/seeed/wio_terminal/wio_terminal.dts:313 */

			/* node '/soc/usb@41000000/board_cdc_acm_uart' defined in zephyr/boards/common/usb/cdc_acm_serial.dtsi:18 */
			board_cdc_acm_uart: board_cdc_acm_uart {
				compatible = "zephyr,cdc-acm-uart"; /* in zephyr/boards/common/usb/cdc_acm_serial.dtsi:19 */
			};
		};

		/* node '/soc/random@42002800' defined in zephyr/dts/arm/atmel/samd5x.dtsi:322 */
		trng: random@42002800 {
			compatible = "atmel,sam-trng"; /* in zephyr/dts/arm/atmel/samd5x.dtsi:323 */
			reg = < 0x42002800 0x1e >;     /* in zephyr/dts/arm/atmel/samd5x.dtsi:324 */
			interrupts = < 0x83 0x0 >;     /* in zephyr/dts/arm/atmel/samd5x.dtsi:325 */
		};

		/* node '/soc/rtc@40002400' defined in zephyr/dts/arm/atmel/samd5x.dtsi:328 */
		rtc: rtc@40002400 {
			compatible = "atmel,sam0-rtc";               /* in zephyr/dts/arm/atmel/samd5x.dtsi:329 */
			reg = < 0x40002400 0x40 >;                   /* in zephyr/dts/arm/atmel/samd5x.dtsi:330 */
			interrupts = < 0xb 0x0 >;                    /* in zephyr/dts/arm/atmel/samd5x.dtsi:331 */
			clocks = < &osc32kctrl >,
			         < &mclk 0x14 0x9 >;                 /* in zephyr/dts/arm/atmel/samd5x.dtsi:332 */
			clock-names = "OSC32KCTRL",
			              "MCLK";                        /* in zephyr/dts/arm/atmel/samd5x.dtsi:333 */
			atmel,assigned-clocks = < &osc32kctrl 0x0 >; /* in zephyr/dts/arm/atmel/samd5x.dtsi:334 */
			atmel,assigned-clock-names = "OSC32KCTRL";   /* in zephyr/dts/arm/atmel/samd5x.dtsi:335 */
			status = "disabled";                         /* in zephyr/dts/arm/atmel/samd5x.dtsi:336 */
			alarms-count = < 0x2 >;                      /* in zephyr/dts/arm/atmel/samd5x.dtsi:338 */
			cal-constant = < 0x100000 >;                 /* in zephyr/dts/arm/atmel/samd5x.dtsi:339 */
		};

		/* node '/soc/adc@43001c00' defined in zephyr/dts/arm/atmel/samd5x.dtsi:342 */
		adc0: adc@43001c00 {
			compatible = "atmel,sam0-adc";         /* in zephyr/dts/arm/atmel/samd5x.dtsi:343 */
			reg = < 0x43001c00 0x4a >;             /* in zephyr/dts/arm/atmel/samd5x.dtsi:344 */
			interrupts = < 0x76 0x0 >,
			             < 0x77 0x0 >;             /* in zephyr/dts/arm/atmel/samd5x.dtsi:345 */
			interrupt-names = "overrun",
			                  "resrdy";            /* in zephyr/dts/arm/atmel/samd5x.dtsi:346 */
			clocks = < &gclk 0x28 >,
			         < &mclk 0x20 0x7 >;           /* in zephyr/dts/arm/atmel/samd5x.dtsi:347 */
			clock-names = "GCLK",
			              "MCLK";                  /* in zephyr/dts/arm/atmel/samd5x.dtsi:348 */
			atmel,assigned-clocks = < &gclk 0x2 >; /* in zephyr/dts/arm/atmel/samd5x.dtsi:356 */
			atmel,assigned-clock-names = "GCLK";   /* in zephyr/dts/arm/atmel/samd5x.dtsi:357 */
			status = "disabled";                   /* in zephyr/dts/arm/atmel/samd5x.dtsi:359 */
			#io-channel-cells = < 0x1 >;           /* in zephyr/dts/arm/atmel/samd5x.dtsi:361 */
			prescaler = < 0x4 >;                   /* in zephyr/dts/arm/atmel/samd5x.dtsi:363 */
			calib-offset = < 0x0 >;                /* in zephyr/dts/arm/atmel/samd5x.dtsi:364 */
		};

		/* node '/soc/adc@43002000' defined in zephyr/dts/arm/atmel/samd5x.dtsi:367 */
		adc1: adc@43002000 {
			compatible = "atmel,sam0-adc";         /* in zephyr/dts/arm/atmel/samd5x.dtsi:368 */
			reg = < 0x43002000 0x4a >;             /* in zephyr/dts/arm/atmel/samd5x.dtsi:369 */
			interrupts = < 0x78 0x0 >,
			             < 0x79 0x0 >;             /* in zephyr/dts/arm/atmel/samd5x.dtsi:370 */
			interrupt-names = "overrun",
			                  "resrdy";            /* in zephyr/dts/arm/atmel/samd5x.dtsi:371 */
			clocks = < &gclk 0x29 >,
			         < &mclk 0x20 0x8 >;           /* in zephyr/dts/arm/atmel/samd5x.dtsi:372 */
			clock-names = "GCLK",
			              "MCLK";                  /* in zephyr/dts/arm/atmel/samd5x.dtsi:373 */
			atmel,assigned-clocks = < &gclk 0x2 >; /* in zephyr/dts/arm/atmel/samd5x.dtsi:381 */
			atmel,assigned-clock-names = "GCLK";   /* in zephyr/dts/arm/atmel/samd5x.dtsi:382 */
			status = "disabled";                   /* in zephyr/dts/arm/atmel/samd5x.dtsi:383 */
			#io-channel-cells = < 0x1 >;           /* in zephyr/dts/arm/atmel/samd5x.dtsi:385 */
			prescaler = < 0x4 >;                   /* in zephyr/dts/arm/atmel/samd5x.dtsi:387 */
			calib-offset = < 0xe >;                /* in zephyr/dts/arm/atmel/samd5x.dtsi:388 */
		};

		/* node '/soc/dac@43002400' defined in zephyr/dts/arm/atmel/samd5x.dtsi:391 */
		dac0: dac@43002400 {
			compatible = "atmel,samd5x-dac";       /* in zephyr/dts/arm/atmel/samd5x.dtsi:392 */
			reg = < 0x43002400 0x20 >;             /* in zephyr/dts/arm/atmel/samd5x.dtsi:393 */
			clocks = < &gclk 0x2a >,
			         < &mclk 0x20 0x9 >;           /* in zephyr/dts/arm/atmel/samd5x.dtsi:395 */
			clock-names = "GCLK",
			              "MCLK";                  /* in zephyr/dts/arm/atmel/samd5x.dtsi:396 */
			atmel,assigned-clocks = < &gclk 0x0 >; /* in zephyr/dts/arm/atmel/samd5x.dtsi:397 */
			atmel,assigned-clock-names = "GCLK";   /* in zephyr/dts/arm/atmel/samd5x.dtsi:398 */
			status = "disabled";                   /* in zephyr/dts/arm/atmel/samd5x.dtsi:399 */
			#io-channel-cells = < 0x1 >;           /* in zephyr/dts/arm/atmel/samd5x.dtsi:401 */
		};

		/* node '/soc/tc@40003800' defined in zephyr/dts/arm/atmel/samd5x.dtsi:404 */
		tc0: tc@40003800 {
			compatible = "atmel,sam0-tc32";        /* in zephyr/dts/arm/atmel/samd5x.dtsi:405 */
			reg = < 0x40003800 0x34 >;             /* in zephyr/dts/arm/atmel/samd5x.dtsi:406 */
			interrupts = < 0x6b 0x0 >;             /* in zephyr/dts/arm/atmel/samd5x.dtsi:407 */
			clocks = < &gclk 0x9 >,
			         < &mclk 0x14 0xe >;           /* in zephyr/dts/arm/atmel/samd5x.dtsi:408 */
			clock-names = "GCLK",
			              "MCLK";                  /* in zephyr/dts/arm/atmel/samd5x.dtsi:409 */
			atmel,assigned-clocks = < &gclk 0x0 >; /* in zephyr/dts/arm/atmel/samd5x.dtsi:410 */
			atmel,assigned-clock-names = "GCLK";   /* in zephyr/dts/arm/atmel/samd5x.dtsi:411 */
			status = "disabled";                   /* in zephyr/dts/arm/atmel/samd5x.dtsi:412 */
		};

		/* node '/soc/tc@4101a000' defined in zephyr/dts/arm/atmel/samd5x.dtsi:415 */
		tc2: tc@4101a000 {
			compatible = "atmel,sam0-tc32";        /* in zephyr/dts/arm/atmel/samd5x.dtsi:416 */
			reg = < 0x4101a000 0x34 >;             /* in zephyr/dts/arm/atmel/samd5x.dtsi:417 */
			interrupts = < 0x6d 0x0 >;             /* in zephyr/dts/arm/atmel/samd5x.dtsi:418 */
			clocks = < &gclk 0x1a >,
			         < &mclk 0x18 0xd >;           /* in zephyr/dts/arm/atmel/samd5x.dtsi:419 */
			clock-names = "GCLK",
			              "MCLK";                  /* in zephyr/dts/arm/atmel/samd5x.dtsi:420 */
			atmel,assigned-clocks = < &gclk 0x0 >; /* in zephyr/dts/arm/atmel/samd5x.dtsi:421 */
			atmel,assigned-clock-names = "GCLK";   /* in zephyr/dts/arm/atmel/samd5x.dtsi:422 */
			status = "disabled";                   /* in zephyr/dts/arm/atmel/samd5x.dtsi:423 */
		};

		/* node '/soc/tc@42001400' defined in zephyr/dts/arm/atmel/samd5x.dtsi:426 */
		tc4: tc@42001400 {
			compatible = "atmel,sam0-tc32";        /* in zephyr/dts/arm/atmel/samd5x.dtsi:427 */
			reg = < 0x42001400 0x34 >;             /* in zephyr/dts/arm/atmel/samd5x.dtsi:428 */
			interrupts = < 0x6f 0x0 >;             /* in zephyr/dts/arm/atmel/samd5x.dtsi:429 */
			clocks = < &gclk 0x1e >,
			         < &mclk 0x1c 0x5 >;           /* in zephyr/dts/arm/atmel/samd5x.dtsi:430 */
			clock-names = "GCLK",
			              "MCLK";                  /* in zephyr/dts/arm/atmel/samd5x.dtsi:431 */
			atmel,assigned-clocks = < &gclk 0x0 >; /* in zephyr/dts/arm/atmel/samd5x.dtsi:432 */
			atmel,assigned-clock-names = "GCLK";   /* in zephyr/dts/arm/atmel/samd5x.dtsi:433 */
			status = "disabled";                   /* in zephyr/dts/arm/atmel/samd5x.dtsi:434 */
		};

		/* node '/soc/tc@43001400' defined in zephyr/dts/arm/atmel/samd5x.dtsi:437 */
		tc6: tc@43001400 {
			compatible = "atmel,sam0-tc32";        /* in zephyr/dts/arm/atmel/samd5x.dtsi:438 */
			reg = < 0x43001400 0x34 >;             /* in zephyr/dts/arm/atmel/samd5x.dtsi:439 */
			interrupts = < 0x71 0x0 >;             /* in zephyr/dts/arm/atmel/samd5x.dtsi:440 */
			clocks = < &gclk 0x27 >,
			         < &mclk 0x20 0x5 >;           /* in zephyr/dts/arm/atmel/samd5x.dtsi:441 */
			clock-names = "GCLK",
			              "MCLK";                  /* in zephyr/dts/arm/atmel/samd5x.dtsi:442 */
			atmel,assigned-clocks = < &gclk 0x0 >; /* in zephyr/dts/arm/atmel/samd5x.dtsi:443 */
			atmel,assigned-clock-names = "GCLK";   /* in zephyr/dts/arm/atmel/samd5x.dtsi:444 */
			status = "disabled";                   /* in zephyr/dts/arm/atmel/samd5x.dtsi:445 */
		};

		/* node '/soc/tcc@41016000' defined in zephyr/dts/arm/atmel/samd5x.dtsi:448 */
		tcc0: tcc@41016000 {
			compatible = "atmel,sam0-tcc";         /* in zephyr/dts/arm/atmel/samd5x.dtsi:449 */
			reg = < 0x41016000 0x2000 >;           /* in zephyr/dts/arm/atmel/samd5x.dtsi:450 */
			interrupts = < 0x55 0x0 >,
			             < 0x56 0x0 >,
			             < 0x57 0x0 >,
			             < 0x58 0x0 >,
			             < 0x59 0x0 >,
			             < 0x5a 0x0 >,
			             < 0x5b 0x0 >;             /* in zephyr/dts/arm/atmel/samd5x.dtsi:451 */
			clocks = < &gclk 0x19 >,
			         < &mclk 0x18 0xb >;           /* in zephyr/dts/arm/atmel/samd5x.dtsi:453 */
			clock-names = "GCLK",
			              "MCLK";                  /* in zephyr/dts/arm/atmel/samd5x.dtsi:454 */
			atmel,assigned-clocks = < &gclk 0x0 >; /* in zephyr/dts/arm/atmel/samd5x.dtsi:455 */
			atmel,assigned-clock-names = "GCLK";   /* in zephyr/dts/arm/atmel/samd5x.dtsi:456 */
			status = "disabled";                   /* in zephyr/dts/arm/atmel/samd5x.dtsi:457 */
			channels = < 0x6 >;                    /* in zephyr/dts/arm/atmel/samd5x.dtsi:459 */
			counter-size = < 0x18 >;               /* in zephyr/dts/arm/atmel/samd5x.dtsi:460 */
		};

		/* node '/soc/tcc@41018000' defined in zephyr/dts/arm/atmel/samd5x.dtsi:463 */
		tcc1: tcc@41018000 {
			compatible = "atmel,sam0-tcc";         /* in zephyr/dts/arm/atmel/samd5x.dtsi:464 */
			reg = < 0x41018000 0x2000 >;           /* in zephyr/dts/arm/atmel/samd5x.dtsi:465 */
			interrupts = < 0x5c 0x0 >,
			             < 0x5d 0x0 >,
			             < 0x5e 0x0 >,
			             < 0x5f 0x0 >,
			             < 0x60 0x0 >;             /* in zephyr/dts/arm/atmel/samd5x.dtsi:466 */
			clocks = < &gclk 0x19 >,
			         < &mclk 0x18 0xc >;           /* in zephyr/dts/arm/atmel/samd5x.dtsi:467 */
			clock-names = "GCLK",
			              "MCLK";                  /* in zephyr/dts/arm/atmel/samd5x.dtsi:468 */
			atmel,assigned-clocks = < &gclk 0x0 >; /* in zephyr/dts/arm/atmel/samd5x.dtsi:469 */
			atmel,assigned-clock-names = "GCLK";   /* in zephyr/dts/arm/atmel/samd5x.dtsi:470 */
			status = "disabled";                   /* in zephyr/dts/arm/atmel/samd5x.dtsi:471 */
			channels = < 0x4 >;                    /* in zephyr/dts/arm/atmel/samd5x.dtsi:473 */
			counter-size = < 0x18 >;               /* in zephyr/dts/arm/atmel/samd5x.dtsi:474 */
		};

		/* node '/soc/tcc@42000c00' defined in zephyr/dts/arm/atmel/samd5x.dtsi:477 */
		tcc2: tcc@42000c00 {
			compatible = "atmel,sam0-tcc";         /* in zephyr/dts/arm/atmel/samd5x.dtsi:478 */
			reg = < 0x42000c00 0x400 >;            /* in zephyr/dts/arm/atmel/samd5x.dtsi:479 */
			interrupts = < 0x61 0x0 >,
			             < 0x62 0x0 >,
			             < 0x63 0x0 >,
			             < 0x64 0x0 >;             /* in zephyr/dts/arm/atmel/samd5x.dtsi:480 */
			clocks = < &gclk 0x1d >,
			         < &mclk 0x1c 0x3 >;           /* in zephyr/dts/arm/atmel/samd5x.dtsi:481 */
			clock-names = "GCLK",
			              "MCLK";                  /* in zephyr/dts/arm/atmel/samd5x.dtsi:482 */
			atmel,assigned-clocks = < &gclk 0x0 >; /* in zephyr/dts/arm/atmel/samd5x.dtsi:483 */
			atmel,assigned-clock-names = "GCLK";   /* in zephyr/dts/arm/atmel/samd5x.dtsi:484 */
			status = "disabled";                   /* in zephyr/dts/arm/atmel/samd5x.dtsi:485 */
			channels = < 0x3 >;                    /* in zephyr/dts/arm/atmel/samd5x.dtsi:487 */
			counter-size = < 0x10 >;               /* in zephyr/dts/arm/atmel/samd5x.dtsi:488 */
		};

		/* node '/soc/tcc@42001000' defined in zephyr/dts/arm/atmel/samd5x.dtsi:491 */
		tcc3: tcc@42001000 {
			compatible = "atmel,sam0-tcc";         /* in zephyr/dts/arm/atmel/samd5x.dtsi:492 */
			reg = < 0x42001000 0x400 >;            /* in zephyr/dts/arm/atmel/samd5x.dtsi:493 */
			interrupts = < 0x65 0x0 >,
			             < 0x66 0x0 >,
			             < 0x67 0x0 >;             /* in zephyr/dts/arm/atmel/samd5x.dtsi:494 */
			clocks = < &gclk 0x1d >,
			         < &mclk 0x1c 0x4 >;           /* in zephyr/dts/arm/atmel/samd5x.dtsi:495 */
			clock-names = "GCLK",
			              "MCLK";                  /* in zephyr/dts/arm/atmel/samd5x.dtsi:496 */
			atmel,assigned-clocks = < &gclk 0x0 >; /* in zephyr/dts/arm/atmel/samd5x.dtsi:497 */
			atmel,assigned-clock-names = "GCLK";   /* in zephyr/dts/arm/atmel/samd5x.dtsi:498 */
			status = "disabled";                   /* in zephyr/dts/arm/atmel/samd5x.dtsi:499 */
			channels = < 0x2 >;                    /* in zephyr/dts/arm/atmel/samd5x.dtsi:501 */
			counter-size = < 0x10 >;               /* in zephyr/dts/arm/atmel/samd5x.dtsi:502 */
		};

		/* node '/soc/tcc@43001000' defined in zephyr/dts/arm/atmel/samd5x.dtsi:505 */
		tcc4: tcc@43001000 {
			compatible = "atmel,sam0-tcc";         /* in zephyr/dts/arm/atmel/samd5x.dtsi:506 */
			reg = < 0x43001000 0x400 >;            /* in zephyr/dts/arm/atmel/samd5x.dtsi:507 */
			interrupts = < 0x68 0x0 >,
			             < 0x69 0x0 >,
			             < 0x6a 0x0 >;             /* in zephyr/dts/arm/atmel/samd5x.dtsi:508 */
			clocks = < &gclk 0x26 >,
			         < &mclk 0x20 0x4 >;           /* in zephyr/dts/arm/atmel/samd5x.dtsi:509 */
			clock-names = "GCLK",
			              "MCLK";                  /* in zephyr/dts/arm/atmel/samd5x.dtsi:510 */
			atmel,assigned-clocks = < &gclk 0x0 >; /* in zephyr/dts/arm/atmel/samd5x.dtsi:511 */
			atmel,assigned-clock-names = "GCLK";   /* in zephyr/dts/arm/atmel/samd5x.dtsi:512 */
			status = "disabled";                   /* in zephyr/dts/arm/atmel/samd5x.dtsi:513 */
			channels = < 0x2 >;                    /* in zephyr/dts/arm/atmel/samd5x.dtsi:515 */
			counter-size = < 0x10 >;               /* in zephyr/dts/arm/atmel/samd5x.dtsi:516 */
		};
	};

	/* node '/cpus' defined in zephyr/dts/arm/atmel/samd5x.dtsi:55 */
	cpus {
		#address-cells = < 0x1 >; /* in zephyr/dts/arm/atmel/samd5x.dtsi:56 */
		#size-cells = < 0x0 >;    /* in zephyr/dts/arm/atmel/samd5x.dtsi:57 */

		/* node '/cpus/cpu@0' defined in zephyr/dts/arm/atmel/samd5x.dtsi:59 */
		cpu0: cpu@0 {
			compatible = "arm,cortex-m4f";   /* in zephyr/dts/arm/atmel/samd5x.dtsi:60 */
			reg = < 0x0 >;                   /* in zephyr/dts/arm/atmel/samd5x.dtsi:61 */
			#address-cells = < 0x1 >;        /* in zephyr/dts/arm/atmel/samd5x.dtsi:63 */
			#size-cells = < 0x1 >;           /* in zephyr/dts/arm/atmel/samd5x.dtsi:64 */
			device_type = "cpu";             /* in zephyr/dts/arm/atmel/samd5x.dtsi:66 */
			clock-frequency = < 0x7270e00 >; /* in zephyr/boards/seeed/wio_terminal/wio_terminal.dts:160 */

			/* node '/cpus/cpu@0/mpu@e000ed90' defined in zephyr/dts/arm/atmel/samd5x.dtsi:68 */
			mpu: mpu@e000ed90 {
				compatible = "arm,armv7m-mpu"; /* in zephyr/dts/arm/atmel/samd5x.dtsi:69 */
				reg = < 0xe000ed90 0x40 >;     /* in zephyr/dts/arm/atmel/samd5x.dtsi:70 */
			};
		};
	};

	/* node '/grove_header0' defined in zephyr/boards/seeed/wio_terminal/grove_connectors.dtsi:7 */
	grove_header0: grove_header0 {
		compatible = "grove-header";               /* in zephyr/boards/seeed/wio_terminal/grove_connectors.dtsi:8 */
		#gpio-cells = < 0x2 >;                     /* in zephyr/boards/seeed/wio_terminal/grove_connectors.dtsi:9 */
		gpio-map-mask = < 0xffffffff 0xffffffc0 >; /* in zephyr/boards/seeed/wio_terminal/grove_connectors.dtsi:10 */
		gpio-map-pass-thru = < 0x0 0x3f >;         /* in zephyr/boards/seeed/wio_terminal/grove_connectors.dtsi:11 */
		gpio-map = < 0x0 0x0 &portb 0x8 0x0 >,
		           < 0x1 0x0 &portb 0x9 0x0 >;     /* in zephyr/boards/seeed/wio_terminal/grove_connectors.dtsi:12 */
	};

	/* node '/grove_header1' defined in zephyr/boards/seeed/wio_terminal/grove_connectors.dtsi:16 */
	grove_header1: grove_header1 {
		compatible = "grove-header";               /* in zephyr/boards/seeed/wio_terminal/grove_connectors.dtsi:17 */
		#gpio-cells = < 0x2 >;                     /* in zephyr/boards/seeed/wio_terminal/grove_connectors.dtsi:18 */
		gpio-map-mask = < 0xffffffff 0xffffffc0 >; /* in zephyr/boards/seeed/wio_terminal/grove_connectors.dtsi:19 */
		gpio-map-pass-thru = < 0x0 0x3f >;         /* in zephyr/boards/seeed/wio_terminal/grove_connectors.dtsi:20 */
		gpio-map = < 0x0 0x0 &porta 0x10 0x0 >,
		           < 0x1 0x0 &porta 0x11 0x0 >;    /* in zephyr/boards/seeed/wio_terminal/grove_connectors.dtsi:21 */
	};

	/* node '/raspberrypi_header' defined in zephyr/boards/seeed/wio_terminal/raspberrypi_40pins_connector.dtsi:7 */
	raspberrypi_header: raspberrypi_header {
		compatible = "raspberrypi-40pins-header";  /* in zephyr/boards/seeed/wio_terminal/raspberrypi_40pins_connector.dtsi:8 */
		#gpio-cells = < 0x2 >;                     /* in zephyr/boards/seeed/wio_terminal/raspberrypi_40pins_connector.dtsi:9 */
		gpio-map-mask = < 0xffffffff 0xffffffc0 >; /* in zephyr/boards/seeed/wio_terminal/raspberrypi_40pins_connector.dtsi:10 */
		gpio-map-pass-thru = < 0x0 0x3f >;         /* in zephyr/boards/seeed/wio_terminal/raspberrypi_40pins_connector.dtsi:11 */
		gpio-map = < 0x0 0x0 &porta 0x11 0x0 >,
		           < 0x1 0x0 &porta 0x10 0x0 >,
		           < 0x2 0x0 &portb 0xe 0x0 >,
		           < 0x3 0x0 &portb 0x1a 0x0 >,
		           < 0x4 0x0 &portb 0x1b 0x0 >,
		           < 0x5 0x0 &porta 0x2 0x0 >,
		           < 0x6 0x0 &portb 0x10 0x0 >,
		           < 0x7 0x0 &portb 0x8 0x0 >,
		           < 0x8 0x0 &portb 0x9 0x0 >,
		           < 0x9 0x0 &porta 0x7 0x0 >,
		           < 0xa 0x0 &portb 0x4 0x0 >,
		           < 0xb 0x0 &portb 0x2 0x0 >,
		           < 0xc 0x0 &portb 0x0 0x0 >,
		           < 0xd 0x0 &portb 0x5 0x0 >,
		           < 0xe 0x0 &portb 0x3 0x0 >,
		           < 0xf 0x0 &portb 0x1 0x0 >,
		           < 0x10 0x0 &porta 0x5 0x0 >,
		           < 0x11 0x0 &porta 0xd 0x0 >,
		           < 0x12 0x0 &porta 0xc 0x0 >,
		           < 0x13 0x0 &portb 0xc 0x0 >,
		           < 0x14 0x0 &portb 0xd 0x0 >,
		           < 0x15 0x0 &portb 0x6 0x0 >,
		           < 0x16 0x0 &porta 0x4 0x0 >,
		           < 0x17 0x0 &porta 0x14 0x0 >,
		           < 0x18 0x0 &portb 0x7 0x0 >,
		           < 0x19 0x0 &porta 0x6 0x0 >,
		           < 0x1a 0x0 &porta 0x15 0x0 >,
		           < 0x1b 0x0 &porta 0x16 0x0 >;   /* in zephyr/boards/seeed/wio_terminal/raspberrypi_40pins_connector.dtsi:12 */
	};

	/* node '/leds' defined in zephyr/boards/seeed/wio_terminal/wio_terminal.dts:40 */
	leds {
		compatible = "gpio-leds"; /* in zephyr/boards/seeed/wio_terminal/wio_terminal.dts:41 */

		/* node '/leds/led_0' defined in zephyr/boards/seeed/wio_terminal/wio_terminal.dts:43 */
		led0: led_0 {
			label = "LED";              /* in zephyr/boards/seeed/wio_terminal/wio_terminal.dts:44 */
			gpios = < &porta 0xf 0x0 >; /* in zephyr/boards/seeed/wio_terminal/wio_terminal.dts:45 */
		};
	};

	/* node '/buttons' defined in zephyr/boards/seeed/wio_terminal/wio_terminal.dts:50 */
	buttons: buttons {
		compatible = "gpio-keys"; /* in zephyr/boards/seeed/wio_terminal/wio_terminal.dts:51 */

		/* node '/buttons/button_0' defined in zephyr/boards/seeed/wio_terminal/wio_terminal.dts:53 */
		user_button_0: button_0 {
			label = "User Button 0";     /* in zephyr/boards/seeed/wio_terminal/wio_terminal.dts:54 */
			gpios = < &portc 0x1a 0x1 >; /* in zephyr/boards/seeed/wio_terminal/wio_terminal.dts:55 */
			zephyr,code = < 0xb >;       /* in zephyr/boards/seeed/wio_terminal/wio_terminal.dts:56 */
		};

		/* node '/buttons/button_1' defined in zephyr/boards/seeed/wio_terminal/wio_terminal.dts:59 */
		user_button_1: button_1 {
			label = "User Button 1";     /* in zephyr/boards/seeed/wio_terminal/wio_terminal.dts:60 */
			gpios = < &portc 0x1b 0x1 >; /* in zephyr/boards/seeed/wio_terminal/wio_terminal.dts:61 */
			zephyr,code = < 0x2 >;       /* in zephyr/boards/seeed/wio_terminal/wio_terminal.dts:62 */
		};

		/* node '/buttons/button_2' defined in zephyr/boards/seeed/wio_terminal/wio_terminal.dts:65 */
		user_button_2: button_2 {
			label = "User Button 2";     /* in zephyr/boards/seeed/wio_terminal/wio_terminal.dts:66 */
			gpios = < &portc 0x1c 0x1 >; /* in zephyr/boards/seeed/wio_terminal/wio_terminal.dts:67 */
			zephyr,code = < 0x3 >;       /* in zephyr/boards/seeed/wio_terminal/wio_terminal.dts:68 */
		};
	};

	/* node '/joystick' defined in zephyr/boards/seeed/wio_terminal/wio_terminal.dts:73 */
	joystick: joystick {
		compatible = "gpio-keys";        /* in zephyr/boards/seeed/wio_terminal/wio_terminal.dts:74 */
		polling-mode;                    /* in zephyr/boards/seeed/wio_terminal/wio_terminal.dts:75 */
		debounce-interval-ms = < 0x64 >; /* in zephyr/boards/seeed/wio_terminal/wio_terminal.dts:76 */

		/* node '/joystick/joystick_selection' defined in zephyr/boards/seeed/wio_terminal/wio_terminal.dts:78 */
		joy_sel: joystick_selection {
			label = "joystick selection"; /* in zephyr/boards/seeed/wio_terminal/wio_terminal.dts:79 */
			gpios = < &portd 0xa 0x1 >;   /* in zephyr/boards/seeed/wio_terminal/wio_terminal.dts:80 */
			zephyr,code = < 0x1c >;       /* in zephyr/boards/seeed/wio_terminal/wio_terminal.dts:81 */
		};

		/* node '/joystick/joystick_down' defined in zephyr/boards/seeed/wio_terminal/wio_terminal.dts:84 */
		joy_down: joystick_down {
			label = "joystick down";    /* in zephyr/boards/seeed/wio_terminal/wio_terminal.dts:85 */
			gpios = < &portd 0x8 0x1 >; /* in zephyr/boards/seeed/wio_terminal/wio_terminal.dts:86 */
			zephyr,code = < 0x6c >;     /* in zephyr/boards/seeed/wio_terminal/wio_terminal.dts:87 */
		};

		/* node '/joystick/joystick_up' defined in zephyr/boards/seeed/wio_terminal/wio_terminal.dts:90 */
		joy_up: joystick_up {
			label = "joystick up";       /* in zephyr/boards/seeed/wio_terminal/wio_terminal.dts:91 */
			gpios = < &portd 0x14 0x1 >; /* in zephyr/boards/seeed/wio_terminal/wio_terminal.dts:92 */
			zephyr,code = < 0x67 >;      /* in zephyr/boards/seeed/wio_terminal/wio_terminal.dts:93 */
		};

		/* node '/joystick/joystick_left' defined in zephyr/boards/seeed/wio_terminal/wio_terminal.dts:96 */
		joy_left: joystick_left {
			label = "joystick left";    /* in zephyr/boards/seeed/wio_terminal/wio_terminal.dts:97 */
			gpios = < &portd 0xc 0x1 >; /* in zephyr/boards/seeed/wio_terminal/wio_terminal.dts:98 */
			zephyr,code = < 0x69 >;     /* in zephyr/boards/seeed/wio_terminal/wio_terminal.dts:99 */
		};

		/* node '/joystick/joystick_right' defined in zephyr/boards/seeed/wio_terminal/wio_terminal.dts:102 */
		joy_right: joystick_right {
			label = "joystick right";   /* in zephyr/boards/seeed/wio_terminal/wio_terminal.dts:103 */
			gpios = < &portd 0x9 0x1 >; /* in zephyr/boards/seeed/wio_terminal/wio_terminal.dts:104 */
			zephyr,code = < 0x6a >;     /* in zephyr/boards/seeed/wio_terminal/wio_terminal.dts:105 */
		};
	};

	/* node '/lcd_backlight_en' defined in zephyr/boards/seeed/wio_terminal/wio_terminal.dts:110 */
	lcd_backlight_en {
		compatible = "regulator-fixed";          /* in zephyr/boards/seeed/wio_terminal/wio_terminal.dts:111 */
		regulator-name = "lcd_backlight_enable"; /* in zephyr/boards/seeed/wio_terminal/wio_terminal.dts:112 */
		enable-gpios = < &portc 0x5 0x0 >;       /* in zephyr/boards/seeed/wio_terminal/wio_terminal.dts:113 */
		regulator-boot-on;                       /* in zephyr/boards/seeed/wio_terminal/wio_terminal.dts:114 */
	};

	/* node '/rpi_power_3v3_en' defined in zephyr/boards/seeed/wio_terminal/wio_terminal.dts:117 */
	rpi_power_3v3_en {
		compatible = "regulator-fixed";          /* in zephyr/boards/seeed/wio_terminal/wio_terminal.dts:118 */
		regulator-name = "rpi_power_3v3_enable"; /* in zephyr/boards/seeed/wio_terminal/wio_terminal.dts:119 */
		enable-gpios = < &portc 0xf 0x1 >;       /* in zephyr/boards/seeed/wio_terminal/wio_terminal.dts:120 */
		regulator-boot-on;                       /* in zephyr/boards/seeed/wio_terminal/wio_terminal.dts:121 */
	};

	/* node '/rpi_power_5v_en' defined in zephyr/boards/seeed/wio_terminal/wio_terminal.dts:124 */
	rpi_power_5v_en {
		compatible = "regulator-fixed";         /* in zephyr/boards/seeed/wio_terminal/wio_terminal.dts:125 */
		regulator-name = "rpi_power_5v_enable"; /* in zephyr/boards/seeed/wio_terminal/wio_terminal.dts:126 */
		enable-gpios = < &portc 0xe 0x0 >;      /* in zephyr/boards/seeed/wio_terminal/wio_terminal.dts:127 */
		regulator-boot-on;                      /* in zephyr/boards/seeed/wio_terminal/wio_terminal.dts:128 */
	};

	/* node '/usb_power_5v_en' defined in zephyr/boards/seeed/wio_terminal/wio_terminal.dts:131 */
	usb_power_5v_en {
		compatible = "regulator-fixed";     /* in zephyr/boards/seeed/wio_terminal/wio_terminal.dts:132 */
		regulator-name = "usb_power_5v_en"; /* in zephyr/boards/seeed/wio_terminal/wio_terminal.dts:133 */
		enable-gpios = < &porta 0x1b 0x1 >; /* in zephyr/boards/seeed/wio_terminal/wio_terminal.dts:134 */
	};

	/* node '/mipi_dbi' defined in zephyr/boards/seeed/wio_terminal/wio_terminal.dts:138 */
	mipi_dbi {
		compatible = "zephyr,mipi-dbi-spi"; /* in zephyr/boards/seeed/wio_terminal/wio_terminal.dts:139 */
		dc-gpios = < &portc 0x6 0x0 >;      /* in zephyr/boards/seeed/wio_terminal/wio_terminal.dts:140 */
		reset-gpios = < &portc 0x7 0x1 >;   /* in zephyr/boards/seeed/wio_terminal/wio_terminal.dts:141 */
		#address-cells = < 0x1 >;           /* in zephyr/boards/seeed/wio_terminal/wio_terminal.dts:142 */
		#size-cells = < 0x0 >;              /* in zephyr/boards/seeed/wio_terminal/wio_terminal.dts:143 */
		spi-dev = < &sercom7 >;             /* in zephyr/boards/seeed/wio_terminal/wio_terminal.dts:144 */
		write-only;                         /* in zephyr/boards/seeed/wio_terminal/wio_terminal.dts:145 */

		/* node '/mipi_dbi/ili9341@0' defined in zephyr/boards/seeed/wio_terminal/wio_terminal.dts:147 */
		ili9341: ili9341@0 {
			compatible = "ilitek,ili9341";      /* in zephyr/boards/seeed/wio_terminal/wio_terminal.dts:148 */
			mipi-max-frequency = < 0x16e3600 >; /* in zephyr/boards/seeed/wio_terminal/wio_terminal.dts:149 */
			reg = < 0x0 >;                      /* in zephyr/boards/seeed/wio_terminal/wio_terminal.dts:150 */
			pixel-format = < 0x0 >;             /* in zephyr/boards/seeed/wio_terminal/wio_terminal.dts:151 */
			rotation = < 0x10e >;               /* in zephyr/boards/seeed/wio_terminal/wio_terminal.dts:152 */
			width = < 0x140 >;                  /* in zephyr/boards/seeed/wio_terminal/wio_terminal.dts:153 */
			height = < 0xf0 >;                  /* in zephyr/boards/seeed/wio_terminal/wio_terminal.dts:154 */
		};
	};
};
